# MDR32F02_rev2 register map
File version: 2.0
CPU: BM-310S, little endian
Registers are 32-bit, read-write, no defined reset value unless marked. A register's access mark holds for its fields unless they carry their own. Offsets are from the block's base; [hi:lo] are bit positions; {n}, {i} and the like mark numbered series.

## RST_CLK — RST_CLK description
Base 0x40020000
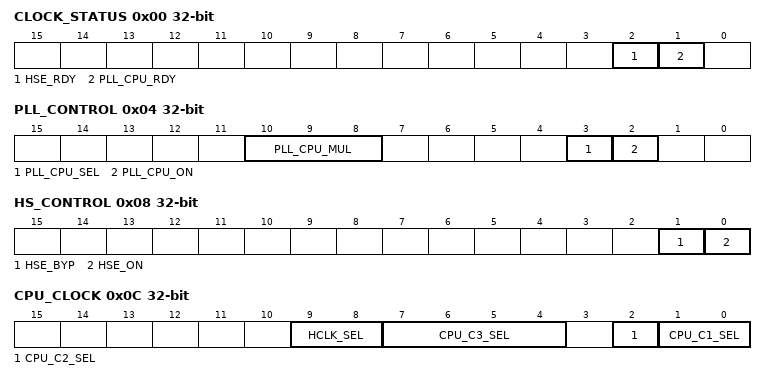
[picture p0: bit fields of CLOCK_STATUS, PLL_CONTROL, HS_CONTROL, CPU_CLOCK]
0x00 CLOCK_STATUS — CLOCK_STATUS description
  [2] HSE_RDY — HSE_RDY description
  [1] PLL_CPU_RDY — PLL_CPU_RDY description
0x04 PLL_CONTROL — PLL_CONTROL description
  [10:8] PLL_CPU_MUL — PLL_CPU_MUL description
  [3] PLL_CPU_SEL — PLL_CPU_SEL description
  [2] PLL_CPU_ON — PLL_CPU_ON description
0x08 HS_CONTROL — HS_CONTROL description
  [1] HSE_BYP — HSE_BYP description
  [0] HSE_ON — HSE_ON description
0x0C CPU_CLOCK — CPU_CLOCK description
  [9:8] HCLK_SEL — HCLK_SEL description
  [7:4] CPU_C3_SEL — CPU_C3_SEL description
  [2] CPU_C2_SEL — CPU_C2_SEL description
  [1:0] CPU_C1_SEL — CPU_C1_SEL description
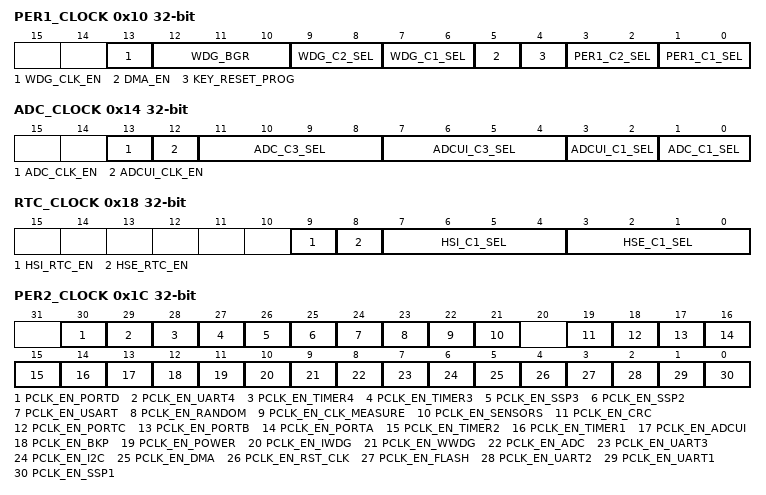
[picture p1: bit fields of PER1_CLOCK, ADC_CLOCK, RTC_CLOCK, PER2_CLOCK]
0x10 PER1_CLOCK — PER1_CLOCK description
  [13] WDG_CLK_EN — WDG_CLK_EN description
  [12:10] WDG_BGR — WDG_BGR description
  [9:8] WDG_C2_SEL — WDG_C2_SEL description
  [7:6] WDG_C1_SEL — WDG_C1_SEL description
  [5] DMA_EN — DMA_EN description
  [4] KEY_RESET_PROG — KEY_RESET_PROG description
  [3:2] PER1_C2_SEL — PER1_C2_SEL description
  [1:0] PER1_C1_SEL — PER1_C1_SEL description
0x14 ADC_CLOCK — ADC_CLOCK description
  [13] ADC_CLK_EN — ADC_CLK_EN description
  [12] ADCUI_CLK_EN — ADCUI_CLK_EN description
  [11:8] ADC_C3_SEL — ADC_C3_SEL description
  [7:4] ADCUI_C3_SEL — ADCUI_C3_SEL description
  [3:2] ADCUI_C1_SEL — ADCUI_C1_SEL description
  [1:0] ADC_C1_SEL — ADC_C1_SEL description
0x18 RTC_CLOCK — RTC_CLOCK description
  [9] HSI_RTC_EN — HSI_RTC_EN description
  [8] HSE_RTC_EN — HSE_RTC_EN description
  [7:4] HSI_C1_SEL — HSI_C1_SEL description
  [3:0] HSE_C1_SEL — HSE_C1_SEL description
0x1C PER2_CLOCK — PER2_CLOCK description
  [30] PCLK_EN_PORTD — PCLK_EN_PORTD description
  [29] PCLK_EN_UART4 — PCLK_EN_UART4 description
  [28] PCLK_EN_TIMER4 — PCLK_EN_TIMER4 description
  [27] PCLK_EN_TIMER3 — PCLK_EN_TIMER3 description
  [26] PCLK_EN_SSP3 — PCLK_EN_SSP3 description
  [25] PCLK_EN_SSP2 — PCLK_EN_SSP2 description
  [24] PCLK_EN_USART — PCLK_EN_USART description
  [23] PCLK_EN_RANDOM — PCLK_EN_RANDOM description
  [22] PCLK_EN_CLK_MEASURE — PCLK_EN_CLK_MEASURE description
  [21] PCLK_EN_SENSORS — PCLK_EN_SENSORS description
  [19] PCLK_EN_CRC — PCLK_EN_CRC description
  [18] PCLK_EN_PORTC — PCLK_EN_PORTC description
  [17] PCLK_EN_PORTB — PCLK_EN_PORTB description
  [16] PCLK_EN_PORTA — PCLK_EN_PORTA description
  [15] PCLK_EN_TIMER2 — PCLK_EN_TIMER2 description
  [14] PCLK_EN_TIMER1 — PCLK_EN_TIMER1 description
  [13] PCLK_EN_ADCUI — PCLK_EN_ADCUI description
  [12] PCLK_EN_BKP — PCLK_EN_BKP description
  [11] PCLK_EN_POWER — PCLK_EN_POWER description
  [10] PCLK_EN_IWDG — PCLK_EN_IWDG description
  [9] PCLK_EN_WWDG — PCLK_EN_WWDG description
  [8] PCLK_EN_ADC — PCLK_EN_ADC description
  [7] PCLK_EN_UART3 — PCLK_EN_UART3 description
  [6] PCLK_EN_I2C — PCLK_EN_I2C description
  [5] PCLK_EN_DMA — PCLK_EN_DMA description
  [4] PCLK_EN_RST_CLK — PCLK_EN_RST_CLK description
  [3] PCLK_EN_FLASH — PCLK_EN_FLASH description
  [2] PCLK_EN_UART2 — PCLK_EN_UART2 description
  [1] PCLK_EN_UART1 — PCLK_EN_UART1 description
  [0] PCLK_EN_SSP1 — PCLK_EN_SSP1 description
0x20 DMA_DONE_STICK — DMA_DONE_STICK description. Rev2
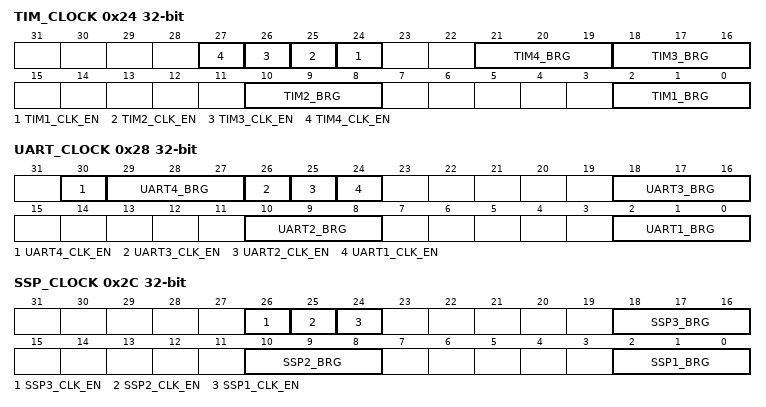
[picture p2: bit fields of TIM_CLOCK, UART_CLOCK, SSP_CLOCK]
0x24 TIM_CLOCK — TIM_CLOCK description
  [n+23] TIM{n}_CLK_EN (n=1..4) — TIM{n}_CLK_EN description
  [21:19] TIM4_BRG — TIM4_BRG description
  [18:16] TIM3_BRG — TIM3_BRG description
  [10:8] TIM2_BRG — TIM2_BRG description
  [2:0] TIM1_BRG — TIM1_BRG description
0x28 UART_CLOCK — UART_CLOCK description
  [30] UART4_CLK_EN — UART4_CLK_EN description
  [29:27] UART4_BRG — UART4_BRG description
  [26] UART3_CLK_EN — UART3_CLK_EN description
  [25] UART2_CLK_EN — UART2_CLK_EN description
  [24] UART1_CLK_EN — UART1_CLK_EN description
  [18:16] UART3_BRG — UART3_BRG description
  [10:8] UART2_BRG — UART2_BRG description
  [2:0] UART1_BRG — UART1_BRG description
0x2C SSP_CLOCK — SSP_CLOCK description
  [26] SSP3_CLK_EN — SSP3_CLK_EN description
  [25] SSP2_CLK_EN — SSP2_CLK_EN description
  [24] SSP1_CLK_EN — SSP1_CLK_EN description
  [18:16] SSP3_BRG — SSP3_BRG description
  [10:8] SSP2_BRG — SSP2_BRG description
  [2:0] SSP1_BRG — SSP1_BRG description
0x30 DIV_SYS_TIM — DIV_SYS_TIM description. Rev2
  [7:0] DIV_SYS_TIM
